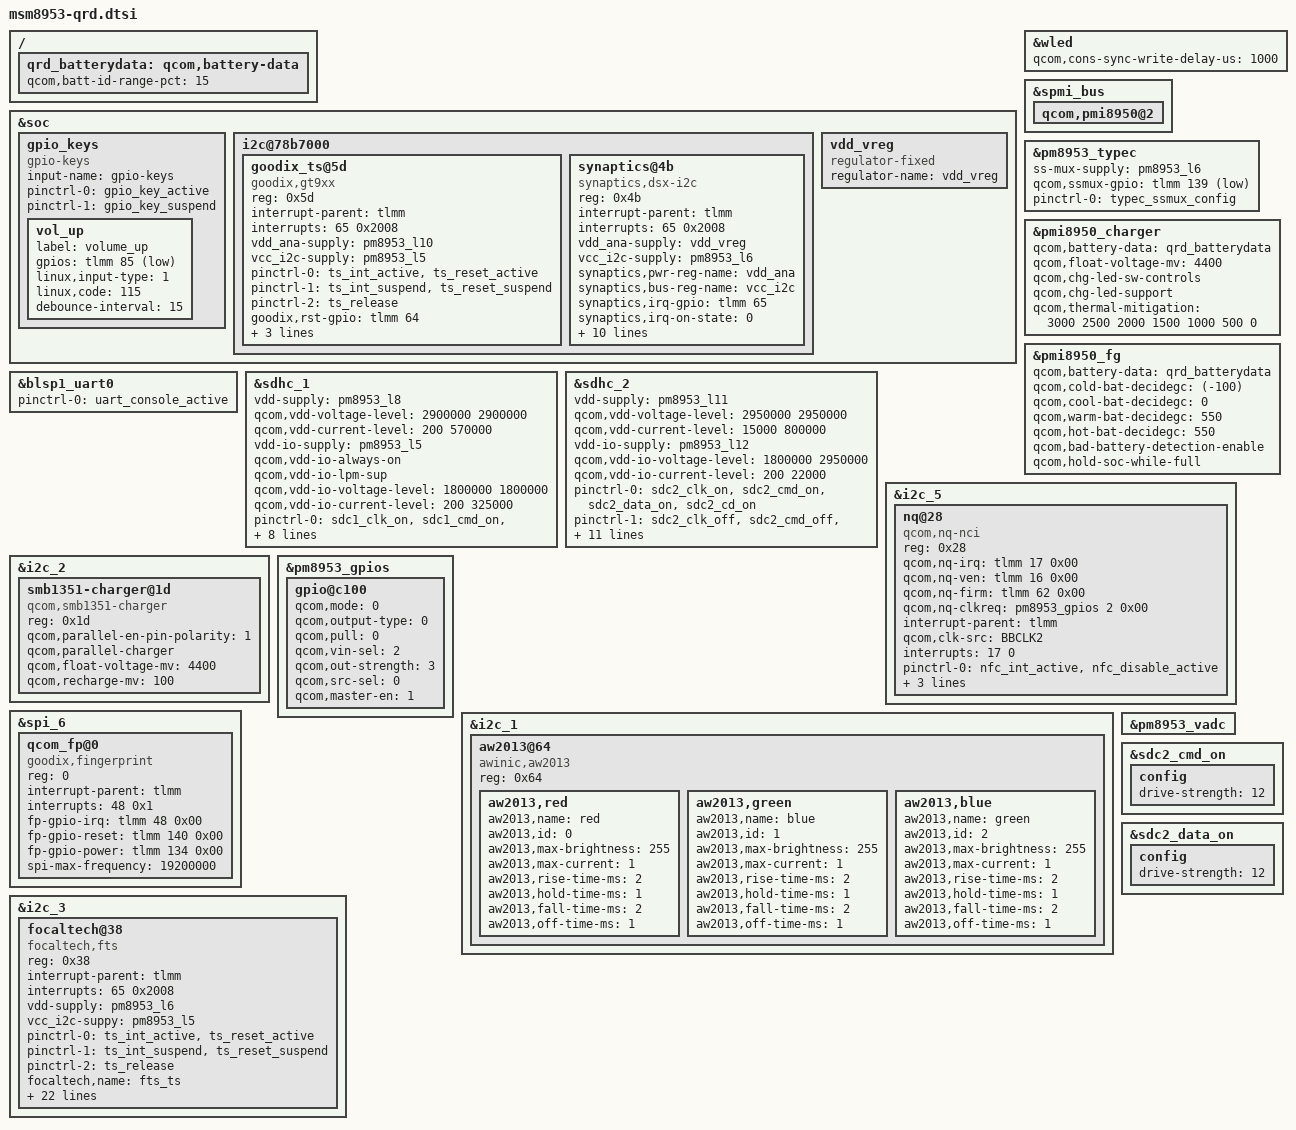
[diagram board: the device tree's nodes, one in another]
/*
 * Copyright (c) 2015-2016, The Linux Foundation. All rights reserved.
 *
 * This program is free software; you can redistribute it and/or modify
 * it under the terms of the GNU General Public License version 2 and
 * only version 2 as published by the Free Software Foundation.
 *
 * This program is distributed in the hope that it will be useful,
 * but WITHOUT ANY WARRANTY; without even the implied warranty of
 * MERCHANTABILITY or FITNESS FOR A PARTICULAR PURPOSE.  See the
 * GNU General Public License for more details.
 */

#include "msm8953-pinctrl.dtsi"
#include "msm8953-camera-sensor-qrd.dtsi"

&soc {
	gpio_keys {
		compatible = "gpio-keys";
		input-name = "gpio-keys";
		pinctrl-names = "tlmm_gpio_key_active","tlmm_gpio_key_suspend";
		pinctrl-0 = <&gpio_key_active>;
		pinctrl-1 = <&gpio_key_suspend>;

		vol_up {
			label = "volume_up";
			gpios = <&tlmm 85 0x1>;
			linux,input-type = <1>;
			linux,code = <115>;
			debounce-interval = <15>;
		};
	};

	i2c@78b7000 { /* BLSP1 QUP3 */
		status = "okay";

		goodix_ts@5d {
			compatible = "goodix,gt9xx";
			reg = <0x5d>;	
			interrupt-parent = <&tlmm>;
			interrupts = <65 0x2008>;
			vdd_ana-supply = <&pm8953_l10>;
			vcc_i2c-supply = <&pm8953_l5>;
			pinctrl-names = "pmx_ts_active","pmx_ts_suspend",
                        "pmx_ts_release";
                        pinctrl-0 = <&ts_int_active &ts_reset_active>;
                        pinctrl-1 = <&ts_int_suspend &ts_reset_suspend>;
                        pinctrl-2 = <&ts_release>;
			goodix,rst-gpio = <&tlmm 64 0x00>;
			goodix,irq-gpio = <&tlmm 65 0x2008>;
			goodix,cfg-group0 = [
				41 D0 02 00 05 05 75 01 01 0F 24 
				0F 64 3C 03 05 00 00 00 02 00 00 
				00 16 19 1C 14 8C 0E 0E 24 00 31 
				0D 00 00 00 83 33 1D 00 41 00 00 
				00 00 00 08 0A 00 2B 1C 3C 94 D5 
				03 08 00 00 04 93 1E 00 82 23 00 
				74 29 00 69 2F 00 5F 37 00 5F 20 
				40 60 00 F0 40 30 55 50 27 00 00 
				00 00 00 00 00 00 00 00 00 00 00 
				00 00 00 00 00 00 00 14 19 00 00 
				50 50 02 04 06 08 0A 0C 0E 10 12 
				14 16 18 1A 1C 00 00 00 00 00 00 
				00 00 00 00 00 00 00 00 00 00 1D 
				1E 1F 20 21 22 24 26 28 29 2A 1C 
				18 16 14 13 12 10 0F 0C 0A 08 06 
				04 02 00 00 00 00 00 00 00 00 00 
				00 00 00 00 00 00 00 00 9C 01];
		};		
		
		synaptics@4b {
			compatible = "synaptics,dsx-i2c";
			reg = <0x4b>;
			interrupt-parent = <&tlmm>;
			interrupts = <65 0x2008>;
			vdd_ana-supply = <&vdd_vreg>;
			vcc_i2c-supply = <&pm8953_l6>;
			synaptics,pwr-reg-name = "vdd_ana";
			synaptics,bus-reg-name = "vcc_i2c";
			synaptics,irq-gpio = <&tlmm 65 0x2008>;
			synaptics,irq-on-state = <0>;
			synaptics,irq-flags = <0x2008>;
			synaptics,power-delay-ms = <200>;
			synaptics,reset-delay-ms = <200>;
			synaptics,max-y-for-2d = <1919>;
			synaptics,cap-button-codes = <139 158 172>;
			synaptics,vir-button-codes = <139 180 2000 320 160
						      158 540 2000 320 160
						      172 900 2000 320 160>;
			synaptics,resume-in-workqueue;
			/* Underlying clocks used by secure touch */
			clock-names = "iface_clk", "core_clk";
			clocks = <&clock_gcc clk_gcc_blsp1_ahb_clk>,
				<&clock_gcc clk_gcc_blsp1_qup3_i2c_apps_clk>;
		};
	};

	vdd_vreg: vdd_vreg {
		compatible = "regulator-fixed";
		status = "ok";
		regulator-name = "vdd_vreg";
	};
};

&wled {
	qcom,cons-sync-write-delay-us = <1000>;
};

&spmi_bus {
	qcom,pmi8950@2 {
		/*qcom,leds@a100 {
			status = "okay";
			qcom,led_mpp_2 {
				label = "mpp";
				linux,name = "green";
				linux,default-trigger = "none";
				qcom,default-state = "off";
				qcom,max-current = <40>;
				qcom,current-setting = <5>;
				qcom,id = <6>;
				qcom,mode = "manual";
				qcom,source-sel = <1>;
				qcom,mode-ctrl = <0x60>;
			};
		};*/
	};
};

/ {
	qrd_batterydata: qcom,battery-data {
		qcom,batt-id-range-pct = <15>;
		#include "batterydata-jiade-atl446580-4v4-3320mah.dtsi"
	};
};

&pm8953_typec {
	ss-mux-supply = <&pm8953_l6>;
	qcom,ssmux-gpio = <&tlmm 139 GPIO_ACTIVE_LOW>;
	pinctrl-names = "default";
	pinctrl-0 = <&typec_ssmux_config>;
};

&pmi8950_charger {
	qcom,battery-data = <&qrd_batterydata>;
	qcom,float-voltage-mv = <4400>;
	qcom,chg-led-sw-controls;
	qcom,chg-led-support;
	//qcom,external-typec;
	//qcom,typec-psy-name = "typec";
	qcom,thermal-mitigation = <3000 2500 2000 1500 1000 500 0>;
	status = "okay";
};

&pmi8950_fg {
	qcom,battery-data = <&qrd_batterydata>;
	qcom,cold-bat-decidegc = <(-100)>;
	qcom,cool-bat-decidegc = <0>;
	qcom,warm-bat-decidegc = <550>;
	qcom,hot-bat-decidegc = <550>;
	qcom,bad-battery-detection-enable;
	qcom,hold-soc-while-full;
};

&blsp1_uart0 {
	status = "ok";
	pinctrl-names = "default";
	pinctrl-0 = <&uart_console_active>;
};

&sdhc_1 {
	/* device core power supply */
	vdd-supply = <&pm8953_l8>;
	qcom,vdd-voltage-level = <2900000 2900000>;
	qcom,vdd-current-level = <200 570000>;

	/* device communication power supply */
	vdd-io-supply = <&pm8953_l5>;
	qcom,vdd-io-always-on;
	qcom,vdd-io-lpm-sup;
	qcom,vdd-io-voltage-level = <1800000 1800000>;
	qcom,vdd-io-current-level = <200 325000>;

	pinctrl-names = "active", "sleep";
	pinctrl-0 = <&sdc1_clk_on &sdc1_cmd_on &sdc1_data_on &sdc1_rclk_on>;
	pinctrl-1 = <&sdc1_clk_off &sdc1_cmd_off &sdc1_data_off &sdc1_rclk_off>;

	qcom,clk-rates = <400000 20000000 25000000 50000000 100000000 192000000
								384000000>;
	qcom,nonremovable;
	qcom,bus-speed-mode = "HS400_1p8v", "HS200_1p8v", "DDR_1p8v";

	status = "ok";
};

&sdhc_2 {
	/* device core power supply */
	vdd-supply = <&pm8953_l11>;
	qcom,vdd-voltage-level = <2950000 2950000>;
	qcom,vdd-current-level = <15000 800000>;

	/* device communication power supply */
	vdd-io-supply = <&pm8953_l12>;
	qcom,vdd-io-voltage-level = <1800000 2950000>;
	qcom,vdd-io-current-level = <200 22000>;

	pinctrl-names = "active", "sleep";
	pinctrl-0 = <&sdc2_clk_on &sdc2_cmd_on &sdc2_data_on &sdc2_cd_on>;
	pinctrl-1 = <&sdc2_clk_off &sdc2_cmd_off &sdc2_data_off &sdc2_cd_off>;

	#address-cells = <0>;
	interrupt-parent = <&sdhc_2>;
	interrupts = <0 1 2>;
	#interrupt-cells = <1>;
	interrupt-map-mask = <0xffffffff>;
	interrupt-map = <0 &intc 0 125 0
		1 &intc 0 221 0
		2 &tlmm 133 0>;
	interrupt-names = "hc_irq", "pwr_irq", "status_irq";
	cd-gpios = <&tlmm 133 0x0>;

	qcom,clk-rates = <400000 20000000 25000000 50000000 100000000
								200000000>;
	qcom,bus-speed-mode = "SDR12", "SDR25", "SDR50", "DDR50", "SDR104";

	status = "ok";
};

&i2c_5 { /* BLSP2 QUP1 (NFC) */
	nq@28 {
		compatible = "qcom,nq-nci";
		reg = <0x28>;
		qcom,nq-irq = <&tlmm 17 0x00>;
		qcom,nq-ven = <&tlmm 16 0x00>;
		qcom,nq-firm = <&tlmm 62 0x00>;
		qcom,nq-clkreq = <&pm8953_gpios 2 0x00>;
		interrupt-parent = <&tlmm>;
		qcom,clk-src = "BBCLK2";
		interrupts = <17 0>;
		interrupt-names = "nfc_irq";
		pinctrl-names = "nfc_active", "nfc_suspend";
		pinctrl-0 = <&nfc_int_active &nfc_disable_active>;
		pinctrl-1 = <&nfc_int_suspend &nfc_disable_suspend>;
		clocks = <&clock_gcc clk_bb_clk2_pin>;
		clock-names = "ref_clk";
	};
};

&i2c_2 {    
       /* Parallel-charger configuration */    
       smb1351-charger@1d {    
       compatible = "qcom,smb1351-charger";    
       reg = <0x1d>;    
       qcom,parallel-en-pin-polarity = <1>;    
       qcom,parallel-charger;    
       qcom,float-voltage-mv = <4400>;    
       qcom,recharge-mv = <100>;    
       };    
 };  

&pm8953_gpios {
	/* GPIO 2 (NFC_CLK_REQ) */
	gpio@c100 {
		qcom,mode = <0>;
		qcom,output-type = <0>;
		qcom,pull = <0>;
		qcom,vin-sel = <2>;
		qcom,out-strength = <3>;
		qcom,src-sel = <0>;
		qcom,master-en = <1>;
		status = "okay";
	};
};

&i2c_1 {  
	aw2013@64 {/* add for breath led. */   
	 status = "okay";   
	compatible = "awinic,aw2013";               
	reg = <0x64>;                               
                                             
	//vcc_i2c-suppy = <&pm8953_l5>;             
	aw2013,red {                                
		aw2013,name = "red";                      
		aw2013,id = <0>;                          
		aw2013,max-brightness = <255>;            
		aw2013,max-current = <1>;                 
		aw2013,rise-time-ms = <2>;                
		aw2013,hold-time-ms = <1>;                
		aw2013,fall-time-ms = <2>;                
		aw2013,off-time-ms = <1>;                 
	};                                          
                                             
	aw2013,green {                              
		aw2013,name = "blue";                     
		aw2013,id = <1>;                          
		aw2013,max-brightness = <255>;            
		aw2013,max-current = <1>;                 
		aw2013,rise-time-ms = <2>;                
		aw2013,hold-time-ms = <1>;                
		aw2013,fall-time-ms = <2>;                
		aw2013,off-time-ms = <1>;                 
	};                                          
                                             
	aw2013,blue {                               
		aw2013,name = "green";                    
		aw2013,id = <2>;                          
		aw2013,max-brightness = <255>;            
		aw2013,max-current = <1>;                 
		aw2013,rise-time-ms = <2>;                
		aw2013,hold-time-ms = <1>;                
		aw2013,fall-time-ms = <2>;                
		aw2013,off-time-ms = <1>;                 
	};                                          
    };                                       
                                             
};                                           
//goodix fingerprint    
&spi_6 { /* BLSP1 QUP3 */    
status = "ok";    
qcom_fp@0 {    
status = "ok";    
compatible = "goodix,fingerprint";    
       reg = <0>;    
       interrupt-parent = <&tlmm>;    
       interrupts = <48 0x1>;    
       fp-gpio-irq = <&tlmm 48 0x00>;    
       fp-gpio-reset = <&tlmm 140 0x00>;    
       fp-gpio-power = <&tlmm 134 0x00>;    
       spi-max-frequency = <19200000>;    
};    
};    

&i2c_3 {
	status = "ok";
		focaltech@38{
			compatible = "focaltech,fts";
			reg = <0x38>;
			interrupt-parent = <&tlmm>;
			interrupts = <65 0x2008>;
			vdd-supply = <&pm8953_l6>;
			vcc_i2c-suppy = <&pm8953_l5>;
			/* pins used by touchscreen */
			pinctrl-names = "pmx_ts_active","pmx_ts_suspend",
				"pmx_ts_release";
			pinctrl-0 = <&ts_int_active &ts_reset_active>;
			pinctrl-1 = <&ts_int_suspend &ts_reset_suspend>;
			pinctrl-2 = <&ts_release>;
			focaltech,name = "fts_ts";
			focaltech,family-id = <0x54>;
			focaltech,reset-gpio = <&tlmm 47 0x00>;
			focaltech,irq-gpio = <&tlmm 65 0x2008>;
			focaltech,display-coords = <0 0 1080 1920>;
			focaltech,panel-coords = <0 0 1080 1920>;
			/*ftech,button-map= <139 102 158>;*/
			focaltech,virtual-key1 = <139 560 2000>;/*menu*/
			focaltech,virtual-key2 = <102 360 2000>;/*home*/
			focaltech,virtual-key3 = <158 160 2000>;/*back*/
			focaltech,no-force-update;
			focaltech,i2c-pull-up;
			focaltech,group-id = <1>;
			focaltech,hard-reset-delay-ms = <20>;
			focaltech,soft-reset-delay-ms = <200>;
			focaltech,num-max-touches = <10>;
			focaltech,fw-delay-aa-ms = <30>;
			focaltech,fw-delay-55-ms = <30>;
			focaltech,fw-upgrade-id1 = <0x79>;
			focaltech,fw-upgrade-id2 = <0x18>;
			focaltech,fw-delay-readid-ms = <10>;
			focaltech,fw-delay-era-flsh-ms = <2000>;
			focaltech,fw-auto-cal;
			focaltech,ignore-id-check;
		};
};
/*
&flash_led {
	/delete-node/ qcom,flash_1;
	/delete-node/ qcom,torch_1;
};

&led_flash0{
	qcom,flash-source = <&pmi8950_flash0>;
	qcom,torch-source = <&pmi8950_torch0>;
};
*/
&pm8953_vadc {
	/delete-node/ chan@11;
};

&sdc2_cmd_on {
	config {
		drive-strength=<12>;
	};
};

&sdc2_data_on {
	config {
		drive-strength=<12>;
	};
};
